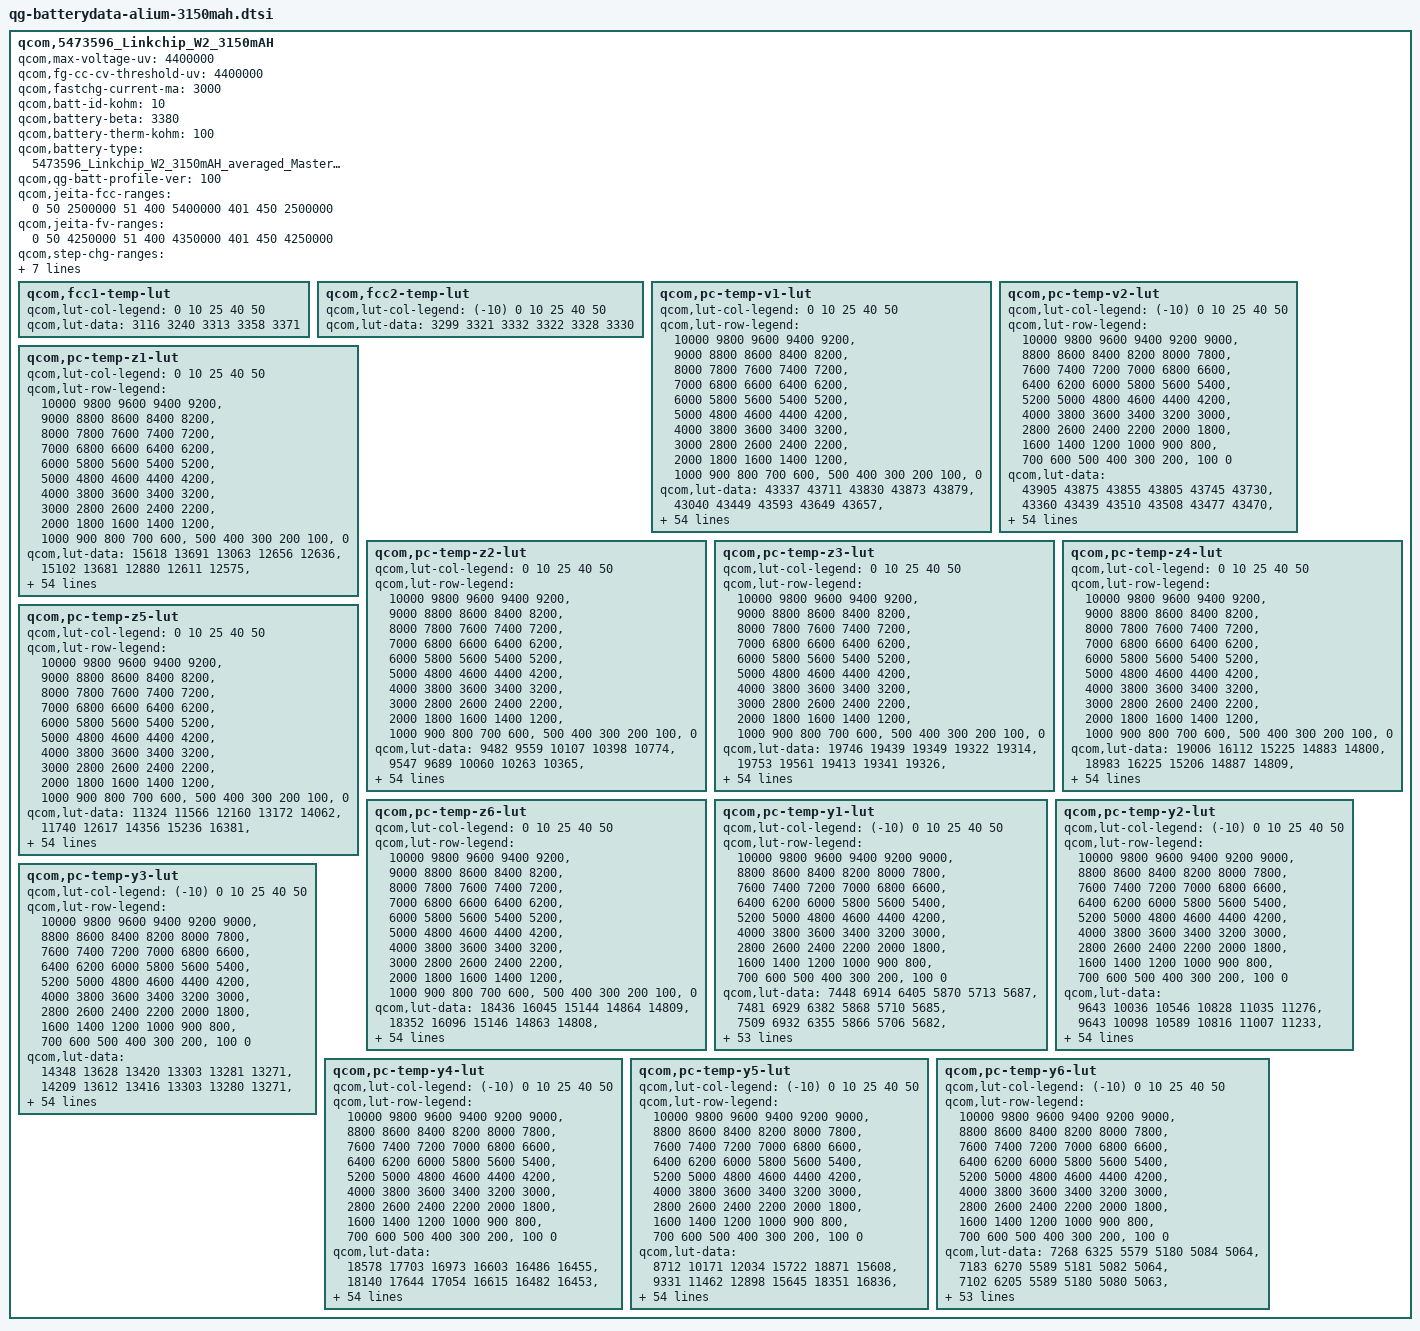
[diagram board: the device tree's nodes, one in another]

qcom,5473596_Linkchip_W2_3150mAH {
    /* 5473596_Linkchip_W2_3150mAH_averaged_MasterSlave_Nov2nd2021 */
    qcom,max-voltage-uv = <4400000>;
    qcom,fg-cc-cv-threshold-uv = <4400000>;
    qcom,fastchg-current-ma = <3000>;
    qcom,batt-id-kohm = <10>;
    qcom,battery-beta = <3380>;
    qcom,battery-therm-kohm = <100>;
    qcom,battery-type = "5473596_Linkchip_W2_3150mAH_averaged_MasterSlave_Nov2nd2021";
    qcom,qg-batt-profile-ver = <100>;

	qcom,jeita-fcc-ranges = <0  50   2500000
				51  400  5400000
				401 450  2500000>;
	qcom,jeita-fv-ranges = <0   50   4250000
				51  400  4350000
				401 450  4250000>;
	qcom,step-chg-ranges = <3600000  3800000  5400000
				3800001  4300000  3600000
				4300001  4350000  2500000>;
	qcom,ocv-based-step-chg;

	/* COOL = 0 DegC, WARM = 55 DegC */
	qcom,jeita-soft-thresholds = <0x58CD 0x181D>;
	/* COLD = -10 DegC, HOT = 65 DegC */
	qcom,jeita-hard-thresholds = <0x6226 0x11A4>;
	/* COOL hys = 8 DegC, WARM hys = 49 DegC */
	qcom,jeita-soft-hys-thresholds = <0x4f5e 0x1D01>;
	qcom,jeita-soft-fcc-ua = <2500000 2500000>;
	qcom,jeita-soft-fv-uv = <4250000 4250000>;

	qcom,fcc1-temp-lut {
		qcom,lut-col-legend = <0 10 25 40 50>;
		qcom,lut-data = <3116 3240 3313 3358 3371>;
	};

	qcom,fcc2-temp-lut {
		qcom,lut-col-legend = <(-10) 0 10 25 40 50>;
		qcom,lut-data = <3299 3321 3332 3322 3328 3330>;
	};

	qcom,pc-temp-v1-lut {
		qcom,lut-col-legend = <0 10 25 40 50>;
		qcom,lut-row-legend = <10000 9800 9600 9400 9200>,
			<9000 8800 8600 8400 8200>,
			<8000 7800 7600 7400 7200>,
			<7000 6800 6600 6400 6200>,
			<6000 5800 5600 5400 5200>,
			<5000 4800 4600 4400 4200>,
			<4000 3800 3600 3400 3200>,
			<3000 2800 2600 2400 2200>,
			<2000 1800 1600 1400 1200>,
			<1000 900 800 700 600>,
			<500 400 300 200 100>,
			<0>;
		qcom,lut-data = <43337 43711 43830 43873 43879>,
			<43040 43449 43593 43649 43657>,
			<42758 43177 43346 43411 43425>,
			<42490 42913 43091 43167 43188>,
			<42235 42659 42835 42917 42941>,
			<41993 42408 42582 42663 42686>,
			<41766 42164 42332 42411 42435>,
			<41549 41934 42088 42164 42191>,
			<41340 41715 41859 41926 41953>,
			<41138 41500 41638 41700 41725>,
			<40935 41290 41420 41479 41502>,
			<40727 41083 41202 41258 41282>,
			<40515 40878 40987 41038 41062>,
			<40295 40671 40778 40823 40846>,
			<40079 40458 40571 40610 40631>,
			<39901 40242 40366 40406 40423>,
			<39757 40049 40165 40209 40224>,
			<39627 39890 39982 40022 40034>,
			<39502 39746 39821 39850 39856>,
			<39385 39600 39663 39685 39688>,
			<39276 39457 39493 39492 39503>,
			<39175 39313 39317 39261 39286>,
			<39079 39174 39113 39047 39075>,
			<38992 39028 38862 38868 38884>,
			<38910 38838 38683 38712 38713>,
			<38825 38614 38600 38583 38576>,
			<38733 38468 38534 38471 38463>,
			<38646 38386 38456 38373 38361>,
			<38578 38329 38375 38287 38267>,
			<38518 38292 38306 38212 38184>,
			<38462 38263 38246 38145 38110>,
			<38405 38239 38193 38087 38044>,
			<38353 38218 38147 38037 37989>,
			<38308 38196 38105 37993 37941>,
			<38270 38171 38065 37951 37894>,
			<38226 38141 38027 37911 37850>,
			<38163 38105 37986 37868 37801>,
			<38092 38062 37943 37816 37742>,
			<38034 38003 37890 37755 37673>,
			<37983 37916 37808 37676 37593>,
			<37914 37807 37697 37576 37501>,
			<37781 37689 37576 37462 37393>,
			<37623 37553 37440 37327 37261>,
			<37464 37395 37284 37176 37114>,
			<37326 37244 37134 37029 36969>,
			<37217 37132 37040 36946 36885>,
			<37159 37094 37010 36920 36860>,
			<37112 37056 36985 36899 36840>,
			<37029 37009 36954 36872 36808>,
			<36805 36890 36882 36789 36720>,
			<36230 36504 36603 36491 36424>,
			<35431 35768 36020 35919 35865>,
			<34567 34841 35148 35108 35084>,
			<33563 33805 34047 34019 34023>,
			<33300 33600 33800 33823 33853>,
			<33100 33400 33600 33600 33600>;
	};

	qcom,pc-temp-v2-lut {
		qcom,lut-col-legend = <(-10) 0 10 25 40 50>;
		qcom,lut-row-legend = <10000 9800 9600 9400 9200 9000>,
			<8800 8600 8400 8200 8000 7800>,
			<7600 7400 7200 7000 6800 6600>,
			<6400 6200 6000 5800 5600 5400>,
			<5200 5000 4800 4600 4400 4200>,
			<4000 3800 3600 3400 3200 3000>,
			<2800 2600 2400 2200 2000 1800>,
			<1600 1400 1200 1000 900 800>,
			<700 600 500 400 300 200>,
			<100 0>;
		qcom,lut-data = <43905 43875 43855 43805 43745 43730>,
			<43360 43439 43510 43508 43477 43470>,
			<42884 43041 43188 43223 43213 43212>,
			<42492 42681 42890 42952 42951 42955>,
			<42160 42351 42614 42693 42694 42699>,
			<41838 42065 42342 42440 42441 42447>,
			<41462 41823 42066 42190 42193 42197>,
			<41191 41595 41806 41950 41952 41956>,
			<41124 41350 41578 41723 41725 41728>,
			<41088 41112 41367 41503 41505 41509>,
			<40962 40935 41156 41285 41286 41290>,
			<40553 40807 40947 41070 41069 41073>,
			<40145 40638 40746 40857 40855 40858>,
			<39853 40327 40555 40650 40646 40645>,
			<39602 39990 40361 40443 40439 40436>,
			<39400 39749 40152 40235 40238 40237>,
			<39232 39546 39936 40030 40042 40044>,
			<39055 39339 39710 39847 39858 39861>,
			<38859 39127 39467 39692 39690 39690>,
			<38672 38930 39235 39521 39509 39509>,
			<38501 38758 39023 39288 39292 39300>,
			<38351 38598 38828 39037 39062 39081>,
			<38257 38421 38656 38831 38855 38873>,
			<38194 38236 38501 38649 38666 38679>,
			<38144 38126 38364 38498 38517 38527>,
			<38102 38068 38240 38372 38397 38406>,
			<38066 38025 38127 38262 38293 38300>,
			<38035 37989 38021 38164 38196 38200>,
			<38007 37958 37937 38076 38108 38109>,
			<37977 37929 37892 37996 38027 38027>,
			<37946 37904 37862 37921 37954 37953>,
			<37909 37882 37833 37856 37888 37887>,
			<37856 37862 37803 37801 37835 37832>,
			<37788 37847 37772 37755 37780 37775>,
			<37712 37841 37736 37720 37717 37709>,
			<37624 37836 37697 37689 37648 37629>,
			<37527 37828 37656 37647 37576 37543>,
			<37418 37797 37612 37586 37502 37454>,
			<37293 37742 37558 37516 37428 37372>,
			<37136 37629 37489 37439 37356 37298>,
			<36947 37475 37403 37353 37278 37223>,
			<36721 37295 37288 37250 37180 37133>,
			<36495 37069 37127 37118 37055 37009>,
			<36323 36774 36926 36974 36917 36876>,
			<36165 36495 36762 36811 36775 36740>,
			<36002 36124 36590 36737 36735 36707>,
			<35907 35902 36495 36702 36709 36683>,
			<35810 35692 36331 36655 36675 36647>,
			<35678 35531 36074 36586 36608 36586>,
			<35464 35373 35745 36459 36455 36429>,
			<35107 35099 35344 36113 36072 36039>,
			<34558 34583 34739 35428 35431 35403>,
			<34319 34336 34545 34935 34956 34934>,
			<34198 34215 34332 34400 34433 34463>,
			<34001 34044 34124 34204 34248 34233>,
			<33900 33987 33987 34004 34048 34033>;
	};

	qcom,pc-temp-z1-lut {
		qcom,lut-col-legend = <0 10 25 40 50>;
		qcom,lut-row-legend = <10000 9800 9600 9400 9200>,
			<9000 8800 8600 8400 8200>,
			<8000 7800 7600 7400 7200>,
			<7000 6800 6600 6400 6200>,
			<6000 5800 5600 5400 5200>,
			<5000 4800 4600 4400 4200>,
			<4000 3800 3600 3400 3200>,
			<3000 2800 2600 2400 2200>,
			<2000 1800 1600 1400 1200>,
			<1000 900 800 700 600>,
			<500 400 300 200 100>,
			<0>;
		qcom,lut-data = <15618 13691 13063 12656 12636>,
			<15102 13681 12880 12611 12575>,
			<14886 13619 12852 12586 12557>,
			<14855 13634 12846 12578 12548>,
			<14816 13651 12812 12569 12543>,
			<14798 13640 12781 12559 12539>,
			<14838 13625 12773 12554 12537>,
			<14875 13607 12769 12552 12538>,
			<14824 13579 12764 12550 12538>,
			<14700 13560 12761 12545 12536>,
			<14645 13554 12758 12539 12533>,
			<14650 13551 12754 12537 12531>,
			<14654 13551 12751 12535 12528>,
			<14629 13552 12752 12535 12527>,
			<14585 13553 12758 12534 12528>,
			<14547 13541 12759 12534 12529>,
			<14515 13529 12754 12535 12530>,
			<14494 13535 12751 12536 12531>,
			<14492 13548 12755 12538 12532>,
			<14498 13555 12761 12541 12533>,
			<14487 13559 12767 12544 12535>,
			<14438 13561 12772 12547 12537>,
			<14394 13560 12775 12550 12540>,
			<14406 13559 12778 12554 12545>,
			<14458 13573 12781 12559 12549>,
			<14490 13627 12789 12562 12553>,
			<14499 13658 12797 12566 12556>,
			<14508 13641 12801 12569 12559>,
			<14535 13621 12804 12573 12561>,
			<14597 13633 12807 12576 12563>,
			<14631 13673 12817 12578 12566>,
			<14595 13688 12828 12581 12569>,
			<14548 13654 12833 12583 12571>,
			<14558 13625 12838 12585 12573>,
			<14600 13632 12839 12587 12574>,
			<14629 13646 12835 12591 12576>,
			<14612 13672 12835 12595 12579>,
			<14585 13739 12847 12600 12582>,
			<14606 13783 12859 12605 12587>,
			<14688 13784 12861 12606 12588>,
			<14757 13777 12859 12608 12588>,
			<14796 13766 12863 12611 12589>,
			<14816 13752 12878 12619 12593>,
			<14796 13758 12896 12622 12598>,
			<14786 13776 12913 12620 12601>,
			<14702 13822 12914 12633 12602>,
			<14707 13826 12913 12636 12602>,
			<14879 13828 12922 12635 12607>,
			<14698 13831 12918 12641 12614>,
			<14789 13838 12938 12648 12617>,
			<14829 13812 12938 12662 12627>,
			<14905 13860 12959 12678 12647>,
			<14935 13935 12999 12712 12683>,
			<14878 13959 13048 12775 12737>,
			<14878 13959 13048 12775 12737>,
			<14878 13959 13048 12775 12737>;
	};

	qcom,pc-temp-z2-lut {
		qcom,lut-col-legend = <0 10 25 40 50>;
		qcom,lut-row-legend = <10000 9800 9600 9400 9200>,
			<9000 8800 8600 8400 8200>,
			<8000 7800 7600 7400 7200>,
			<7000 6800 6600 6400 6200>,
			<6000 5800 5600 5400 5200>,
			<5000 4800 4600 4400 4200>,
			<4000 3800 3600 3400 3200>,
			<3000 2800 2600 2400 2200>,
			<2000 1800 1600 1400 1200>,
			<1000 900 800 700 600>,
			<500 400 300 200 100>,
			<0>;
		qcom,lut-data = <9482 9559 10107 10398 10774>,
			<9547 9689 10060 10263 10365>,
			<9563 9866 10206 10422 10368>,
			<9549 10039 10276 10276 10336>,
			<9563 10085 10245 10274 10295>,
			<9600 10119 10212 10237 10298>,
			<9631 10171 10178 10232 10306>,
			<9662 10193 10154 10236 10315>,
			<9701 10204 10153 10241 10326>,
			<9742 10206 10156 10250 10351>,
			<9774 10197 10165 10264 10385>,
			<9801 10175 10197 10279 10400>,
			<9822 10132 10227 10293 10405>,
			<9835 10071 10231 10300 10404>,
			<9845 10025 10232 10307 10400>,
			<9845 9983 10236 10318 10403>,
			<9832 9957 10245 10350 10441>,
			<9816 9961 10254 10388 10488>,
			<9803 9977 10261 10406 10494>,
			<9788 10004 10272 10415 10492>,
			<9770 10051 10342 10419 10495>,
			<9744 10105 10450 10489 10527>,
			<9717 10171 10441 10549 10554>,
			<9693 10224 10337 10514 10550>,
			<9669 10238 10287 10452 10537>,
			<9664 10242 10302 10460 10480>,
			<9806 10246 10336 10486 10337>,
			<9933 10237 10430 10475 10273>,
			<9922 10227 10611 10382 10262>,
			<9890 10241 10659 10300 10257>,
			<9860 10275 10578 10263 10266>,
			<9837 10298 10508 10242 10286>,
			<9812 10313 10486 10257 10314>,
			<9782 10327 10473 10305 10358>,
			<9745 10341 10484 10353 10404>,
			<9722 10355 10534 10402 10460>,
			<9876 10367 10564 10440 10499>,
			<10097 10381 10568 10463 10515>,
			<10110 10396 10567 10477 10524>,
			<10019 10412 10573 10475 10531>,
			<9970 10425 10588 10467 10549>,
			<10010 10432 10578 10458 10553>,
			<10046 10435 10509 10449 10516>,
			<10056 10410 10477 10430 10494>,
			<9956 10378 10451 10412 10485>,
			<9802 10365 10344 10443 10493>,
			<9786 10314 10301 10442 10474>,
			<9525 10287 10315 10446 10489>,
			<9386 10219 10293 10457 10507>,
			<9489 10228 10308 10442 10516>,
			<9909 10216 10317 10300 10322>,
			<9822 10008 10131 10179 10177>,
			<9616 9735 9975 10042 10047>,
			<9429 9445 9767 9949 9973>,
			<9429 9445 9767 9949 9973>,
			<9429 9445 9767 9949 9973>;
	};

	qcom,pc-temp-z3-lut {
		qcom,lut-col-legend = <0 10 25 40 50>;
		qcom,lut-row-legend = <10000 9800 9600 9400 9200>,
			<9000 8800 8600 8400 8200>,
			<8000 7800 7600 7400 7200>,
			<7000 6800 6600 6400 6200>,
			<6000 5800 5600 5400 5200>,
			<5000 4800 4600 4400 4200>,
			<4000 3800 3600 3400 3200>,
			<3000 2800 2600 2400 2200>,
			<2000 1800 1600 1400 1200>,
			<1000 900 800 700 600>,
			<500 400 300 200 100>,
			<0>;
		qcom,lut-data = <19746 19439 19349 19322 19314>,
			<19753 19561 19413 19341 19326>,
			<19747 19673 19437 19355 19333>,
			<19724 19703 19477 19364 19337>,
			<19700 19713 19478 19374 19349>,
			<19699 19712 19477 19374 19352>,
			<19700 19702 19473 19373 19351>,
			<19701 19684 19466 19369 19344>,
			<19702 19657 19455 19364 19339>,
			<19703 19639 19441 19358 19337>,
			<19702 19627 19432 19352 19335>,
			<19698 19618 19427 19349 19332>,
			<19694 19609 19423 19347 19327>,
			<19691 19602 19417 19346 19325>,
			<19688 19597 19411 19345 19325>,
			<19683 19589 19408 19344 19325>,
			<19673 19576 19406 19340 19324>,
			<19661 19562 19404 19335 19322>,
			<19648 19546 19397 19332 19319>,
			<19635 19532 19393 19330 19317>,
			<19621 19519 19395 19331 19317>,
			<19608 19511 19400 19344 19319>,
			<19596 19507 19399 19351 19324>,
			<19585 19504 19394 19347 19333>,
			<19575 19505 19391 19342 19344>,
			<19576 19512 19388 19355 19349>,
			<19623 19515 19384 19384 19352>,
			<19666 19511 19399 19392 19353>,
			<19665 19506 19436 19388 19351>,
			<19659 19503 19447 19382 19349>,
			<19651 19501 19445 19377 19346>,
			<19641 19499 19443 19371 19342>,
			<19628 19496 19437 19366 19338>,
			<19608 19493 19427 19360 19334>,
			<19578 19491 19420 19356 19331>,
			<19560 19490 19412 19352 19328>,
			<19617 19489 19408 19350 19326>,
			<19696 19487 19405 19349 19327>,
			<19693 19485 19403 19349 19329>,
			<19647 19483 19401 19348 19329>,
			<19614 19480 19400 19346 19327>,
			<19604 19478 19397 19342 19325>,
			<19596 19475 19392 19338 19320>,
			<19583 19471 19390 19338 19320>,
			<19543 19461 19389 19341 19323>,
			<19506 19443 19372 19330 19318>,
			<19507 19438 19369 19329 19316>,
			<19469 19435 19364 19325 19310>,
			<19383 19425 19360 19318 19310>,
			<19490 19439 19362 19327 19317>,
			<19579 19463 19391 19353 19336>,
			<19650 19529 19411 19373 19355>,
			<19756 19563 19436 19389 19367>,
			<19838 19553 19427 19388 19372>,
			<19838 19553 19427 19388 19372>,
			<19838 19553 19427 19388 19372>;
	};

	qcom,pc-temp-z4-lut {
		qcom,lut-col-legend = <0 10 25 40 50>;
		qcom,lut-row-legend = <10000 9800 9600 9400 9200>,
			<9000 8800 8600 8400 8200>,
			<8000 7800 7600 7400 7200>,
			<7000 6800 6600 6400 6200>,
			<6000 5800 5600 5400 5200>,
			<5000 4800 4600 4400 4200>,
			<4000 3800 3600 3400 3200>,
			<3000 2800 2600 2400 2200>,
			<2000 1800 1600 1400 1200>,
			<1000 900 800 700 600>,
			<500 400 300 200 100>,
			<0>;
		qcom,lut-data = <19006 16112 15225 14883 14800>,
			<18983 16225 15206 14887 14809>,
			<18919 16465 15102 14833 14768>,
			<18536 16145 15218 14842 14779>,
			<17835 15819 15099 14863 14797>,
			<17309 15607 14987 14817 14769>,
			<16911 15437 14920 14781 14744>,
			<16591 15307 14869 14754 14728>,
			<16351 15202 14830 14737 14714>,
			<16156 15115 14801 14726 14703>,
			<15988 15039 14784 14718 14694>,
			<15839 14979 14774 14711 14689>,
			<15721 14929 14767 14705 14684>,
			<15635 14890 14762 14699 14679>,
			<15562 14874 14758 14691 14671>,
			<15483 14868 14754 14685 14663>,
			<15394 14862 14747 14680 14657>,
			<15318 14836 14741 14675 14651>,
			<15268 14808 14735 14672 14647>,
			<15229 14803 14731 14669 14644>,
			<15208 14804 14740 14678 14649>,
			<15194 14807 14763 14731 14697>,
			<15185 14815 14812 14781 14739>,
			<15181 14832 14936 14811 14749>,
			<15179 14894 15002 14828 14754>,
			<15171 15025 14984 14809 14747>,
			<15119 15082 14953 14760 14724>,
			<15070 15092 14914 14739 14709>,
			<15064 15096 14867 14732 14700>,
			<15062 15083 14843 14729 14693>,
			<15065 15051 14832 14727 14689>,
			<15073 15021 14825 14726 14686>,
			<15083 14990 14822 14725 14683>,
			<15096 14961 14820 14723 14680>,
			<15121 14935 14820 14723 14680>,
			<15130 14911 14820 14726 14685>,
			<15058 14895 14820 14728 14692>,
			<14955 14881 14820 14731 14697>,
			<14916 14876 14820 14734 14701>,
			<14891 14882 14821 14733 14700>,
			<14881 14889 14823 14729 14693>,
			<14885 14886 14822 14725 14688>,
			<14888 14874 14811 14719 14684>,
			<14876 14861 14800 14715 14683>,
			<14829 14825 14780 14712 14683>,
			<14806 14765 14730 14684 14663>,
			<14801 14757 14722 14671 14653>,
			<14824 14744 14708 14659 14641>,
			<14902 14735 14696 14651 14631>,
			<14805 14725 14694 14653 14637>,
			<14870 14796 14716 14675 14659>,
			<14972 14844 14751 14713 14689>,
			<14959 14847 14746 14726 14716>,
			<14983 14865 14740 14703 14702>,
			<14983 14865 14740 14703 14702>,
			<14983 14865 14740 14703 14702>;
	};

	qcom,pc-temp-z5-lut {
		qcom,lut-col-legend = <0 10 25 40 50>;
		qcom,lut-row-legend = <10000 9800 9600 9400 9200>,
			<9000 8800 8600 8400 8200>,
			<8000 7800 7600 7400 7200>,
			<7000 6800 6600 6400 6200>,
			<6000 5800 5600 5400 5200>,
			<5000 4800 4600 4400 4200>,
			<4000 3800 3600 3400 3200>,
			<3000 2800 2600 2400 2200>,
			<2000 1800 1600 1400 1200>,
			<1000 900 800 700 600>,
			<500 400 300 200 100>,
			<0>;
		qcom,lut-data = <11324 11566 12160 13172 14062>,
			<11740 12617 14356 15236 16381>,
			<12243 12757 15675 17675 18480>,
			<12845 13164 15173 17637 18285>,
			<13555 13634 15719 16933 18074>,
			<14290 14108 16408 17296 19044>,
			<15061 14608 17129 17885 19409>,
			<15789 15056 17816 18657 19286>,
			<16417 15494 18352 18990 19225>,
			<16989 16126 18831 18960 19841>,
			<17592 17073 19352 18942 20580>,
			<18319 18029 19998 19078 20422>,
			<18878 19169 20549 19328 19813>,
			<19076 20625 20841 19751 19714>,
			<19192 21187 21115 20593 20584>,
			<19401 21198 21475 21026 21756>,
			<19925 21253 22397 20919 22688>,
			<20348 22116 23428 20844 23580>,
			<20293 24013 24270 21155 24751>,
			<20019 25571 25286 21911 26133>,
			<19617 26890 27505 23580 26425>,
			<18830 28393 30075 28336 25475>,
			<17981 30586 29835 30802 23987>,
			<17366 32749 26671 24303 20889>,
			<16842 34733 23685 16816 17668>,
			<17002 37550 20676 17372 17545>,
			<21665 38641 18293 20674 18562>,
			<26053 36041 19343 22863 19685>,
			<26483 32736 22711 24129 20880>,
			<26601 30937 25103 25119 22162>,
			<26518 29654 26890 26092 23597>,
			<26346 28664 28047 27054 25133>,
			<26138 27650 28636 28014 26724>,
			<25591 26956 29015 28888 28338>,
			<24350 26891 29007 29028 28760>,
			<23414 27100 28698 28501 28299>,
			<26941 27472 28217 27697 27587>,
			<32082 28242 27151 26425 26324>,
			<32246 28774 25811 24783 24617>,
			<30141 28973 24439 23259 23411>,
			<28985 29024 22965 21748 22450>,
			<31318 28228 21762 20402 21301>,
			<33204 26230 20749 19134 19541>,
			<31438 25132 20363 18793 18809>,
			<28224 24930 20438 18790 18711>,
			<22786 25289 20551 18303 19168>,
			<22458 23536 19815 18897 19276>,
			<16826 23191 19470 18923 19421>,
			<13434 21875 19856 18721 24073>,
			<17599 28055 21294 22674 26962>,
			<25639 27217 25483 25589 25449>,
			<19595 21621 23590 26276 25277>,
			<18862 18930 22204 26260 24598>,
			<17554 16336 19019 25357 26627>,
			<17554 16336 19019 25357 26627>,
			<17554 16336 19019 25357 26627>;
	};

	qcom,pc-temp-z6-lut {
		qcom,lut-col-legend = <0 10 25 40 50>;
		qcom,lut-row-legend = <10000 9800 9600 9400 9200>,
			<9000 8800 8600 8400 8200>,
			<8000 7800 7600 7400 7200>,
			<7000 6800 6600 6400 6200>,
			<6000 5800 5600 5400 5200>,
			<5000 4800 4600 4400 4200>,
			<4000 3800 3600 3400 3200>,
			<3000 2800 2600 2400 2200>,
			<2000 1800 1600 1400 1200>,
			<1000 900 800 700 600>,
			<500 400 300 200 100>,
			<0>;
		qcom,lut-data = <18436 16045 15144 14864 14809>,
			<18352 16096 15146 14863 14808>,
			<18205 16215 15098 14842 14790>,
			<17925 16059 15160 14847 14795>,
			<17556 15890 15100 14860 14808>,
			<17277 15769 15041 14837 14798>,
			<17058 15664 15004 14820 14787>,
			<16878 15575 14973 14805 14776>,
			<16740 15499 14945 14794 14767>,
			<16626 15437 14922 14784 14760>,
			<16521 15386 14908 14777 14755>,
			<16421 15345 14899 14772 14750>,
			<16333 15312 14892 14768 14745>,
			<16261 15288 14885 14764 14741>,
			<16196 15276 14880 14760 14738>,
			<16133 15269 14875 14756 14734>,
			<16069 15260 14871 14752 14731>,
			<16015 15244 14867 14747 14727>,
			<15975 15228 14862 14744 14724>,
			<15942 15222 14858 14742 14722>,
			<15923 15219 14863 14747 14723>,
			<15910 15218 14877 14777 14745>,
			<15903 15222 14901 14803 14768>,
			<15900 15232 14952 14815 14781>,
			<15900 15262 14979 14822 14789>,
			<15902 15324 14969 14821 14788>,
			<15909 15351 14956 14817 14782>,
			<15917 15354 14952 14813 14776>,
			<15923 15355 14951 14809 14772>,
			<15927 15349 14949 14804 14768>,
			<15931 15337 14944 14801 14764>,
			<15933 15325 14940 14797 14761>,
			<15933 15313 14935 14794 14758>,
			<15929 15302 14931 14791 14754>,
			<15923 15293 14928 14789 14753>,
			<15921 15286 14925 14788 14754>,
			<15930 15284 14924 14787 14755>,
			<15943 15284 14924 14789 14758>,
			<15946 15284 14924 14790 14761>,
			<15944 15290 14925 14790 14760>,
			<15945 15299 14928 14788 14757>,
			<15953 15301 14927 14785 14754>,
			<15959 15302 14923 14781 14750>,
			<15954 15301 14920 14781 14750>,
			<15923 15292 14915 14782 14753>,
			<15903 15267 14888 14765 14742>,
			<15904 15262 14884 14760 14737>,
			<15894 15259 14877 14753 14730>,
			<15885 15255 14873 14748 14726>,
			<15917 15268 14877 14755 14733>,
			<16022 15328 14909 14782 14756>,
			<16128 15414 14950 14816 14785>,
			<16214 15483 14990 14845 14813>,
			<16315 15542 15019 14854 14822>,
			<16315 15542 15019 14854 14822>,
			<16315 15542 15019 14854 14822>;
	};

	qcom,pc-temp-y1-lut {
		qcom,lut-col-legend = <(-10) 0 10 25 40 50>;
		qcom,lut-row-legend = <10000 9800 9600 9400 9200 9000>,
			<8800 8600 8400 8200 8000 7800>,
			<7600 7400 7200 7000 6800 6600>,
			<6400 6200 6000 5800 5600 5400>,
			<5200 5000 4800 4600 4400 4200>,
			<4000 3800 3600 3400 3200 3000>,
			<2800 2600 2400 2200 2000 1800>,
			<1600 1400 1200 1000 900 800>,
			<700 600 500 400 300 200>,
			<100 0>;
		qcom,lut-data = <7448 6914 6405 5870 5713 5687>,
			<7481 6929 6382 5868 5710 5685>,
			<7509 6932 6355 5866 5706 5682>,
			<7531 6928 6331 5863 5703 5680>,
			<7546 6919 6314 5860 5699 5678>,
			<7549 6908 6309 5856 5696 5676>,
			<7541 6886 6312 5852 5692 5674>,
			<7533 6871 6317 5849 5688 5673>,
			<7532 6872 6323 5849 5684 5670>,
			<7531 6874 6328 5850 5681 5668>,
			<7525 6881 6325 5848 5679 5667>,
			<7491 6901 6315 5840 5678 5666>,
			<7473 6909 6312 5837 5677 5666>,
			<7509 6905 6326 5839 5676 5666>,
			<7554 6898 6339 5841 5676 5667>,
			<7542 6890 6323 5838 5677 5667>,
			<7495 6882 6298 5834 5677 5667>,
			<7485 6881 6297 5833 5677 5667>,
			<7571 6895 6307 5837 5676 5668>,
			<7641 6907 6312 5840 5676 5669>,
			<7613 6906 6315 5842 5677 5669>,
			<7563 6901 6317 5842 5679 5670>,
			<7562 6900 6318 5843 5680 5671>,
			<7595 6913 6319 5845 5681 5672>,
			<7612 6922 6320 5847 5682 5673>,
			<7589 6912 6323 5850 5685 5674>,
			<7565 6905 6326 5854 5686 5675>,
			<7564 6937 6328 5857 5686 5677>,
			<7566 6984 6330 5860 5686 5679>,
			<7568 6985 6343 5863 5689 5681>,
			<7570 6945 6364 5867 5695 5682>,
			<7573 6912 6370 5872 5699 5684>,
			<7576 6888 6369 5882 5702 5686>,
			<7580 6876 6366 5889 5705 5688>,
			<7571 6900 6354 5890 5708 5689>,
			<7532 6934 6344 5892 5710 5690>,
			<7520 6939 6350 5894 5711 5692>,
			<7606 6933 6363 5898 5713 5695>,
			<7688 6935 6375 5902 5714 5697>,
			<7667 6984 6387 5906 5717 5699>,
			<7623 7001 6386 5911 5721 5702>,
			<7611 6972 6400 5918 5727 5704>,
			<7622 6984 6389 5923 5730 5705>,
			<7652 7003 6398 5926 5732 5708>,
			<7716 7003 6421 5940 5738 5712>,
			<7734 6999 6391 5939 5745 5715>,
			<7629 7006 6431 5934 5754 5716>,
			<7628 6998 6402 5944 5755 5721>,
			<7688 7014 6443 5948 5762 5724>,
			<7705 7017 6416 5953 5769 5731>,
			<7816 7036 6430 5958 5781 5744>,
			<7881 7007 6463 5967 5805 5762>,
			<7954 7063 6510 5985 5807 5776>,
			<7899 7159 6529 6021 5828 5792>,
			<7899 7159 6529 6021 5828 5792>,
			<7899 7159 6529 6021 5828 5792>;
	};

	qcom,pc-temp-y2-lut {
		qcom,lut-col-legend = <(-10) 0 10 25 40 50>;
		qcom,lut-row-legend = <10000 9800 9600 9400 9200 9000>,
			<8800 8600 8400 8200 8000 7800>,
			<7600 7400 7200 7000 6800 6600>,
			<6400 6200 6000 5800 5600 5400>,
			<5200 5000 4800 4600 4400 4200>,
			<4000 3800 3600 3400 3200 3000>,
			<2800 2600 2400 2200 2000 1800>,
			<1600 1400 1200 1000 900 800>,
			<700 600 500 400 300 200>,
			<100 0>;
		qcom,lut-data = <9643 10036 10546 10828 11035 11276>,
			<9643 10098 10589 10816 11007 11233>,
			<9643 10188 10636 10799 10971 11163>,
			<9854 10282 10677 10780 10933 11087>,
			<10035 10354 10704 10766 10903 11031>,
			<10068 10381 10711 10758 10888 11016>,
			<9873 10384 10698 10752 10879 11019>,
			<9690 10388 10688 10749 10872 11023>,
			<9839 10513 10693 10748 10863 11021>,
			<10193 10724 10709 10747 10854 11014>,
			<10395 10740 10739 10744 10856 10999>,
			<10524 10645 10818 10743 10876 10963>,
			<10572 10603 10910 10747 10885 10933>,
			<10207 10753 11026 10762 10844 10910>,
			<9745 10914 11121 10785 10800 10894>,
			<9704 10917 11166 10819 10812 10902>,
			<9713 10896 11198 10880 10858 10926>,
			<9716 10873 11198 10965 10921 10943>,
			<9710 10839 11147 11105 11029 10997>,
			<9702 10803 11100 11197 11101 11059>,
			<9697 10767 11083 11217 11105 11137>,
			<9693 10730 11069 11220 11091 11196>,
			<9690 10679 11051 11190 11081 11197>,
			<9688 10611 11031 11123 11072 11191>,
			<9687 10588 11010 11083 11086 11192>,
			<9685 10594 10985 11059 11147 11230>,
			<9683 10599 10954 11048 11187 11268>,
			<9681 10588 10902 11063 11193 11273>,
			<9678 10562 10861 11095 11196 11279>,
			<9675 10533 10860 11125 11204 11310>,
			<9672 10498 10870 11167 11220 11364>,
			<9669 10424 10882 11170 11234 11370>,
			<9667 10125 10908 11137 11250 11322>,
			<9665 9834 10943 11112 11253 11299>,
			<9664 9772 10985 11121 11235 11305>,
			<9662 9745 11026 11141 11208 11307>,
			<9661 9724 11025 11138 11188 11289>,
			<9660 9708 10955 11098 11168 11248>,
			<9659 9695 10871 11073 11145 11230>,
			<9658 9683 10804 11078 11105 11253>,
			<9658 9677 10785 11077 11077 11258>,
			<9657 9675 10824 11091 11049 11228>,
			<9657 9673 10903 11073 11047 11147>,
			<9657 9671 10824 11029 11021 11154>,
			<9656 9668 10821 11026 10990 11060>,
			<9655 9665 10630 11059 10939 10992>,
			<9655 9664 10605 11093 10975 10956>,
			<9654 9662 10589 11129 11045 10922>,
			<9653 9660 10624 11205 11056 10904>,
			<9652 9657 10538 11269 11055 10817>,
			<9650 9654 9914 11144 11076 10811>,
			<9648 9651 9736 10930 11104 10793>,
			<9647 9648 9676 10776 10872 10779>,
			<9647 9647 9653 10629 10707 10729>,
			<9647 9647 9653 10629 10707 10729>,
			<9647 9647 9653 10629 10707 10729>;
	};

	qcom,pc-temp-y3-lut {
		qcom,lut-col-legend = <(-10) 0 10 25 40 50>;
		qcom,lut-row-legend = <10000 9800 9600 9400 9200 9000>,
			<8800 8600 8400 8200 8000 7800>,
			<7600 7400 7200 7000 6800 6600>,
			<6400 6200 6000 5800 5600 5400>,
			<5200 5000 4800 4600 4400 4200>,
			<4000 3800 3600 3400 3200 3000>,
			<2800 2600 2400 2200 2000 1800>,
			<1600 1400 1200 1000 900 800>,
			<700 600 500 400 300 200>,
			<100 0>;
		qcom,lut-data = <14348 13628 13420 13303 13281 13271>,
			<14209 13612 13416 13303 13280 13271>,
			<14073 13595 13411 13304 13279 13272>,
			<13949 13580 13406 13304 13278 13273>,
			<13843 13570 13402 13305 13278 13274>,
			<13761 13567 13399 13305 13278 13274>,
			<13697 13571 13398 13306 13279 13274>,
			<13649 13575 13397 13307 13279 13275>,
			<13612 13537 13398 13307 13279 13275>,
			<13584 13466 13399 13307 13279 13276>,
			<13580 13454 13398 13308 13279 13276>,
			<13586 13462 13389 13310 13281 13277>,
			<13590 13466 13383 13313 13282 13278>,
			<13587 13465 13381 13315 13284 13278>,
			<13582 13464 13379 13316 13285 13278>,
			<13577 13457 13376 13314 13286 13279>,
			<13572 13442 13373 13312 13287 13280>,
			<13571 13429 13368 13310 13288 13282>,
			<13572 13418 13356 13310 13289 13283>,
			<13573 13413 13347 13309 13290 13284>,
			<13568 13418 13343 13306 13288 13283>,
			<13560 13425 13339 13301 13285 13280>,
			<13560 13420 13336 13297 13281 13277>,
			<13570 13400 13333 13294 13276 13273>,
			<13582 13391 13332 13292 13275 13272>,
			<13595 13389 13333 13291 13275 13272>,
			<13609 13388 13334 13290 13275 13272>,
			<13625 13387 13330 13291 13276 13272>,
			<13644 13387 13325 13291 13278 13272>,
			<13663 13387 13326 13291 13278 13272>,
			<13682 13387 13333 13292 13277 13272>,
			<13703 13389 13339 13293 13277 13272>,
			<13724 13399 13344 13292 13278 13273>,
			<13747 13414 13348 13292 13278 13273>,
			<13774 13430 13349 13294 13278 13273>,
			<13806 13448 13349 13298 13278 13273>,
			<13843 13467 13347 13300 13278 13273>,
			<13889 13485 13342 13302 13277 13272>,
			<13938 13503 13339 13304 13276 13272>,
			<13982 13524 13339 13307 13279 13273>,
			<14025 13544 13342 13310 13280 13273>,
			<14073 13558 13351 13316 13279 13273>,
			<14095 13565 13362 13317 13282 13274>,
			<14010 13566 13366 13310 13281 13274>,
			<14081 13590 13368 13311 13281 13275>,
			<14198 13627 13370 13319 13287 13279>,
			<14271 13646 13376 13324 13291 13281>,
			<14389 13681 13381 13329 13298 13283>,
			<14550 13760 13387 13336 13303 13288>,
			<14856 13911 13386 13341 13306 13289>,
			<15632 14187 13391 13334 13303 13290>,
			<17538 14873 13423 13320 13302 13292>,
			<22532 16729 13572 13314 13297 13290>,
			<35670 21951 14260 13318 13294 13289>,
			<35670 21951 14260 13318 13294 13289>,
			<35670 21951 14260 13318 13294 13289>;
	};

	qcom,pc-temp-y4-lut {
		qcom,lut-col-legend = <(-10) 0 10 25 40 50>;
		qcom,lut-row-legend = <10000 9800 9600 9400 9200 9000>,
			<8800 8600 8400 8200 8000 7800>,
			<7600 7400 7200 7000 6800 6600>,
			<6400 6200 6000 5800 5600 5400>,
			<5200 5000 4800 4600 4400 4200>,
			<4000 3800 3600 3400 3200 3000>,
			<2800 2600 2400 2200 2000 1800>,
			<1600 1400 1200 1000 900 800>,
			<700 600 500 400 300 200>,
			<100 0>;
		qcom,lut-data = <18578 17703 16973 16603 16486 16455>,
			<18140 17644 17054 16615 16482 16453>,
			<17877 17568 17102 16620 16478 16450>,
			<17744 17494 17124 16619 16474 16447>,
			<17696 17441 17132 16615 16471 16444>,
			<17696 17428 17127 16609 16469 16443>,
			<17813 17435 17049 16596 16468 16443>,
			<17987 17451 16985 16584 16467 16443>,
			<18170 17541 16991 16577 16468 16444>,
			<18354 17711 17011 16573 16470 16446>,
			<18319 17824 17051 16574 16473 16448>,
			<17884 17914 17138 16587 16479 16452>,
			<17591 17939 17208 16604 16485 16457>,
			<17552 17697 17255 16624 16492 16463>,
			<17530 17426 17281 16646 16502 16470>,
			<17512 17381 17260 16668 16512 16477>,
			<17497 17363 17203 16693 16524 16485>,
			<17473 17332 17141 16729 16545 16498>,
			<17410 17276 17054 16794 16583 16523>,
			<17366 17220 16972 16829 16603 16542>,
			<17367 17166 16905 16771 16591 16547>,
			<17376 17119 16852 16674 16567 16540>,
			<17402 17092 16820 16613 16532 16509>,
			<17485 17070 16797 16566 16481 16461>,
			<17573 17073 16776 16550 16467 16449>,
			<17647 17168 16751 16545 16467 16449>,
			<17721 17297 16731 16544 16467 16449>,
			<17800 17407 16722 16550 16470 16451>,
			<17882 17521 16724 16559 16476 16456>,
			<17965 17639 16753 16561 16483 16461>,
			<18055 17764 16824 16560 16491 16469>,
			<18131 17891 16903 16559 16501 16478>,
			<18191 18021 16991 16559 16515 16491>,
			<18236 18153 17091 16561 16523 16499>,
			<18248 18290 17204 16576 16516 16496>,
			<18249 18429 17333 16609 16496 16483>,
			<18242 18557 17481 16638 16484 16470>,
			<18205 18683 17649 16663 16478 16456>,
			<18137 18734 17774 16692 16476 16452>,
			<18009 18670 17853 16727 16482 16453>,
			<17807 18539 17873 16770 16494 16459>,
			<17576 18330 17820 16819 16508 16465>,
			<17375 17981 17505 16813 16512 16463>,
			<17103 17344 17156 16705 16506 16464>,
			<17097 17252 17224 16737 16509 16457>,
			<17144 17059 17264 16804 16541 16479>,
			<17175 16968 17273 16843 16565 16491>,
			<17225 16940 17200 16892 16591 16508>,
			<17259 16976 17061 16947 16621 16530>,
			<17297 17056 16955 17005 16654 16543>,
			<17485 17052 16930 16962 16681 16560>,
			<18061 17037 16845 16810 16702 16594>,
			<20050 17469 16853 16673 16655 16604>,
			<30435 20259 17129 16665 16612 16611>,
			<30435 20259 17129 16665 16612 16611>,
			<30435 20259 17129 16665 16612 16611>;
	};

	qcom,pc-temp-y5-lut {
		qcom,lut-col-legend = <(-10) 0 10 25 40 50>;
		qcom,lut-row-legend = <10000 9800 9600 9400 9200 9000>,
			<8800 8600 8400 8200 8000 7800>,
			<7600 7400 7200 7000 6800 6600>,
			<6400 6200 6000 5800 5600 5400>,
			<5200 5000 4800 4600 4400 4200>,
			<4000 3800 3600 3400 3200 3000>,
			<2800 2600 2400 2200 2000 1800>,
			<1600 1400 1200 1000 900 800>,
			<700 600 500 400 300 200>,
			<100 0>;
		qcom,lut-data = <8712 10171 12034 15722 18871 15608>,
			<9331 11462 12898 15645 18351 16836>,
			<11800 12802 13810 15665 17580 17707>,
			<13327 14054 14665 15754 16772 18264>,
			<14080 15081 15359 15883 16141 18550>,
			<14172 15763 15800 16032 15888 18591>,
			<12938 16283 16123 16296 15831 18211>,
			<11776 16548 16283 16487 15771 17761>,
			<12804 15608 16166 16308 15401 17557>,
			<15315 13883 15842 15869 14789 17367>,
			<16956 14028 15238 15498 14500 17036>,
			<18173 16270 14026 15134 14512 16464>,
			<18661 17437 13539 14757 14592 15854>,
			<16767 17410 14598 14290 14417 15069>,
			<14366 17344 15993 13822 14146 14507>,
			<14302 17226 16916 13445 14003 14563>,
			<14789 16985 17651 13130 13815 14730>,
			<14946 16798 17772 13135 13788 14749>,
			<14703 16647 17647 13734 13826 14613>,
			<14331 16582 17579 14636 13942 14617>,
			<13752 16983 17602 16361 15841 16213>,
			<13111 17521 17636 18035 18133 18184>,
			<13031 16804 17482 18187 18090 18357>,
			<13198 14292 17073 18102 17353 18220>,
			<13414 12991 17011 17911 16973 18121>,
			<13685 12617 17335 17184 16837 18042>,
			<14014 12432 17445 16615 16795 17976>,
			<14370 12375 16015 16537 17186 17613>,
			<14767 12349 13999 16501 17579 16875>,
			<15171 12372 13400 16659 17284 16467>,
			<15591 12482 13162 17234 16536 16161>,
			<15991 12635 12932 17414 16310 16208>,
			<16333 12852 12681 16455 16844 16422>,
			<16662 13139 12458 15446 17586 16729>,
			<17043 13527 12235 15158 18259 17588>,
			<17485 14042 12059 14974 18845 18686>,
			<18005 14575 12009 14681 18480 18870>,
			<18724 15124 12010 14165 16821 18629>,
			<19376 15631 12062 13684 15999 18227>,
			<19796 16078 12305 13289 16320 17529>,
			<20058 16555 12700 13015 15903 16849>,
			<19735 17171 13256 12964 14852 16430>,
			<18853 17833 14463 13275 15342 16588>,
			<17450 18309 15913 14630 15200 16156>,
			<16222 19251 16864 14792 15680 17897>,
			<16067 19080 17647 14760 15460 17320>,
			<15979 17689 18431 14812 15282 16488>,
			<16243 15749 18981 14854 15542 15476>,
			<16395 15062 18862 15097 15247 15808>,
			<16076 14951 17236 15919 15355 15567>,
			<14060 14868 15403 17672 15871 16468>,
			<11364 13112 14919 18805 17158 17012>,
			<9727 10661 14203 18868 18640 18203>,
			<9055 9383 12262 18812 19036 19364>,
			<9055 9383 12262 18812 19036 19364>,
			<9055 9383 12262 18812 19036 19364>;
	};

	qcom,pc-temp-y6-lut {
		qcom,lut-col-legend = <(-10) 0 10 25 40 50>;
		qcom,lut-row-legend = <10000 9800 9600 9400 9200 9000>,
			<8800 8600 8400 8200 8000 7800>,
			<7600 7400 7200 7000 6800 6600>,
			<6400 6200 6000 5800 5600 5400>,
			<5200 5000 4800 4600 4400 4200>,
			<4000 3800 3600 3400 3200 3000>,
			<2800 2600 2400 2200 2000 1800>,
			<1600 1400 1200 1000 900 800>,
			<700 600 500 400 300 200>,
			<100 0>;
		qcom,lut-data = <7268 6325 5579 5180 5084 5064>,
			<7183 6270 5589 5181 5082 5064>,
			<7102 6205 5589 5180 5080 5063>,
			<7025 6143 5581 5178 5079 5062>,
			<6953 6094 5567 5175 5077 5062>,
			<6885 6067 5547 5172 5076 5062>,
			<6808 6052 5513 5166 5075 5062>,
			<6759 6043 5489 5161 5075 5062>,
			<6787 6037 5488 5158 5075 5062>,
			<6848 6032 5488 5154 5075 5063>,
			<6846 6038 5491 5155 5075 5064>,
			<6745 6067 5506 5160 5078 5066>,
			<6650 6079 5519 5165 5081 5068>,
			<6594 6015 5528 5172 5084 5069>,
			<6555 5938 5533 5178 5088 5071>,
			<6540 5913 5526 5184 5091 5074>,
			<6533 5899 5508 5189 5095 5078>,
			<6522 5881 5485 5197 5102 5083>,
			<6500 5858 5451 5215 5114 5091>,
			<6484 5843 5420 5225 5120 5097>,
			<6480 5839 5398 5206 5115 5097>,
			<6477 5836 5382 5174 5105 5093>,
			<6483 5827 5372 5154 5092 5082>,
			<6519 5814 5365 5139 5074 5065>,
			<6559 5813 5362 5133 5070 5060>,
			<6595 5846 5359 5132 5070 5060>,
			<6635 5892 5358 5132 5070 5060>,
			<6679 5932 5356 5134 5072 5061>,
			<6727 5975 5358 5137 5074 5063>,
			<6776 6022 5372 5140 5077 5065>,
			<6828 6073 5405 5141 5079 5067>,
			<6879 6126 5440 5142 5082 5070>,
			<6927 6181 5476 5143 5087 5074>,
			<6973 6238 5515 5145 5090 5077>,
			<7016 6303 5557 5153 5088 5076>,
			<7058 6374 5600 5167 5083 5073>,
			<7096 6446 5648 5180 5080 5069>,
			<7140 6521 5698 5191 5078 5065>,
			<7168 6564 5741 5203 5078 5064>,
			<7166 6578 5775 5218 5081 5065>,
			<7158 6579 5794 5236 5086 5067>,
			<7138 6536 5798 5258 5091 5070>,
			<7110 6457 5739 5259 5094 5070>,
			<6979 6289 5665 5224 5092 5070>,
			<7045 6295 5702 5239 5094 5069>,
			<7167 6292 5732 5269 5110 5080>,
			<7247 6297 5746 5287 5120 5085>,
			<7366 6336 5742 5308 5134 5092>,
			<7522 6442 5718 5332 5147 5102>,
			<7810 6624 5698 5356 5161 5108>,
			<8588 6890 5710 5341 5170 5116>,
			<10366 7484 5752 5292 5178 5130>,
			<14693 9167 5986 5256 5164 5134>,
			<26039 13812 6818 5267 5153 5137>,
			<26039 13812 6818 5267 5153 5137>,
			<26039 13812 6818 5267 5153 5137>;
	};

};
